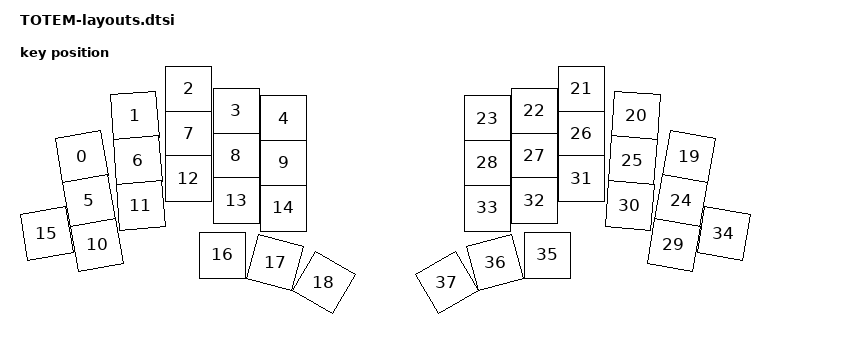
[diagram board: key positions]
// Generated by importing the TOTEM Kicad files into Nick Coustos's Keymap
// Layout Helper (https://nickcoutsos.github.io/keymap-layout-tools/)
// and feeding the output of that into the tool at
// https://zmk-physical-layout-converter.streamlit.app/

#include <physical_layouts.dtsi>

/ {
    TOTEM_layout: TOTEM_layout {
        compatible = "zmk,physical-layout";
        display-name = "Default";

        kscan = <&kscan0>;
        transform = <&matrix_transform0>;

        keys  //                     w   h    x    y     rot    rx    ry
            = <&key_physical_attrs 100 100   70  136 (-1000)   120   186>
            , <&key_physical_attrs 100 100  176   54  (-400)   226   104>
            , <&key_physical_attrs 100 100  284    0       0     0     0>
            , <&key_physical_attrs 100 100  379   44       0     0     0>
            , <&key_physical_attrs 100 100  474   59       0     0     0>
            , <&key_physical_attrs 100 100   85  224 (-1000)   135   274>
            , <&key_physical_attrs 100 100  182  143  (-400)   232   193>
            , <&key_physical_attrs 100 100  284   90       0     0     0>
            , <&key_physical_attrs 100 100  379  134       0     0     0>
            , <&key_physical_attrs 100 100  474  148       0     0     0>
            , <&key_physical_attrs 100 100  101  312 (-1000)   151   362>
            , <&key_physical_attrs 100 100  188  233  (-400)   238   283>
            , <&key_physical_attrs 100 100  284  179       0     0     0>
            , <&key_physical_attrs 100 100  379  223       0     0     0>
            , <&key_physical_attrs 100 100  474  238       0     0     0>
            , <&key_physical_attrs 100 100    0  289 (-1000)    50   339>
            , <&key_physical_attrs 100 100  352  332       0     0     0>
            , <&key_physical_attrs 100 100  457  347    1500   507   397>
            , <&key_physical_attrs 100 100  554  387    3000   604   437>
            , <&key_physical_attrs 100 100 1285  136    1000  1335   186>
            , <&key_physical_attrs 100 100 1179   54     400  1229   104>
            , <&key_physical_attrs 100 100 1070    0       0     0     0>
            , <&key_physical_attrs 100 100  975   44       0     0     0>
            , <&key_physical_attrs 100 100  881   59       0     0     0>
            , <&key_physical_attrs 100 100 1269  224    1000  1319   274>
            , <&key_physical_attrs 100 100 1172  143     400  1222   193>
            , <&key_physical_attrs 100 100 1070   90       0     0     0>
            , <&key_physical_attrs 100 100  975  134       0     0     0>
            , <&key_physical_attrs 100 100  881  148       0     0     0>
            , <&key_physical_attrs 100 100 1254  312    1000  1304   362>
            , <&key_physical_attrs 100 100 1166  233     400  1216   283>
            , <&key_physical_attrs 100 100 1070  179       0     0     0>
            , <&key_physical_attrs 100 100  975  223       0     0     0>
            , <&key_physical_attrs 100 100  881  238       0     0     0>
            , <&key_physical_attrs 100 100 1354  289    1000  1404   339>
            , <&key_physical_attrs 100 100 1002  332       0     0     0>
            , <&key_physical_attrs 100 100  897  347 (-1500)   947   397>
            , <&key_physical_attrs 100 100  800  387 (-3000)   850   437>
            ;
    };
};
